# CH585SFR register map
Vendor: WCH Ltd.; Series: CH58x; File version: 1.1
CPU: RISC-V r0p0, little endian, no MPU, no FPU, 2 interrupt priority bits
Registers are 8-bit, read-write, reset 0x0 unless marked. A register's access mark holds for its fields unless they carry their own. Offsets are from the block's base; [hi:lo] are bit positions.

## TMR3 — Timer3 register
Base 0x40002C00
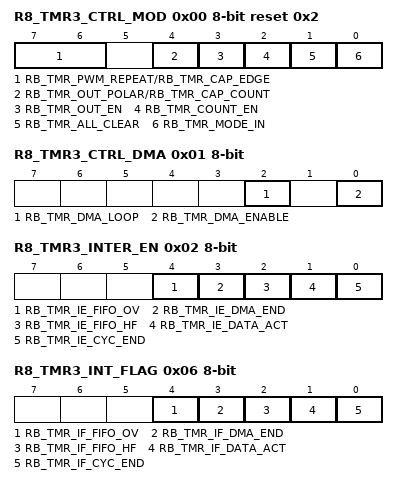
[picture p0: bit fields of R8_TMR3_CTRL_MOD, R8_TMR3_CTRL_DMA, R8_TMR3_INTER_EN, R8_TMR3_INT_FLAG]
0x00 R8_TMR3_CTRL_MOD reset 0x2 — RW, TMR3 mode control
  [7:6] RB_TMR_PWM_REPEAT/RB_TMR_CAP_EDGE — RW, timer PWM repeat mode: 00=1, 01=4, 10=8, 11-16;RW, timer capture edge mode: 00=disable, 01=edge change, 10=fall to fall, 11-rise to rise
  [4] RB_TMR_OUT_POLAR/RB_TMR_CAP_COUNT — RW, timer PWM output polarity: 0=default low and high action, 1=default high and low action;RW, count sub-mode if RB_TMR_MODE_IN=1: 0=capture, 1=count
  [3] RB_TMR_OUT_EN — RW, timer output enable
  [2] RB_TMR_COUNT_EN — RW, timer count enable
  [1] RB_TMR_ALL_CLEAR — RW, force clear timer FIFO and count
  [0] RB_TMR_MODE_IN — RW, timer in mode: 0=timer/PWM, 1=capture/count
0x01 R8_TMR3_CTRL_DMA — RW, TMR3 DMA control
  [2] RB_TMR_DMA_LOOP — RW, timer3 DMA address loop enable
  [0] RB_TMR_DMA_ENABLE — RW, timer3 DMA enable
0x02 R8_TMR3_INTER_EN — RW, TMR3 interrupt enable
  [4] RB_TMR_IE_FIFO_OV — RW, enable interrupt for timer FIFO overflow
  [3] RB_TMR_IE_DMA_END — RW, enable interrupt for timer1/2 DMA completion
  [2] RB_TMR_IE_FIFO_HF — RW, enable interrupt for timer FIFO half (capture fifo more than 4 or PWM fifo less than 3)
  [1] RB_TMR_IE_DATA_ACT — RW, enable interrupt for timer capture input action or PWM trigger
  [0] RB_TMR_IE_CYC_END — RW, enable interrupt for timer capture count timeout or PWM cycle end
0x06 R8_TMR3_INT_FLAG — RW1, TMR3 interrupt flag
  [4] RB_TMR_IF_FIFO_OV — RW1, interrupt flag for timer FIFO overflow
  [3] RB_TMR_IF_DMA_END — RW1, interrupt flag for timer1/2 DMA completion
  [2] RB_TMR_IF_FIFO_HF — RW1, interrupt flag for timer FIFO half (capture fifo more than 4 or PWM fifo less than 3)
  [1] RB_TMR_IF_DATA_ACT — RW1, interrupt flag for timer capture input action or PWM trigger
  [0] RB_TMR_IF_CYC_END — RW1, interrupt flag for timer capture count timeout or PWM cycle end
0x07 R8_TMR3_FIFO_COUNT ro reset not defined — RO, TMR3 FIFO count status
  [3:0] R8_TMR3_FIFO_COUNT
0x08 R32_TMR3_COUNT 32-bit ro reset not defined — RO, TMR3 current count
  [25:0] R32_TMR3_COUNT
0x0C R32_TMR3_CNT_END 32-bit reset not defined — RW, TMR3 end count value, only low 26 bit
0x10 R32_TMR3_FIFO 32-bit reset not defined — RO/WO, TMR3 FIFO register, only low 26 bit
0x14 R16_TMR2_DMA_NOW 16-bit ro reset not defined — RO, TMR2 DMA current address
  [16:2] R16_TMR2_DMA_NOW — RO, DMA data buffer current address
0x18 R16_TMR3_DMA_BEG 16-bit reset not defined — RW, TMR3 DMA begin address
  [16:2] R16_TMR3_DMA_BEG — RW, TMR3 DMA data buffer start address
0x1C R16_TMR3_DMA_END 16-bit reset not defined — RW, TMR3 DMA end address
  [16:2] R16_TMR3_DMA_END — RW, TMR2 DMA end address

## SPI0
Base 0x40004000
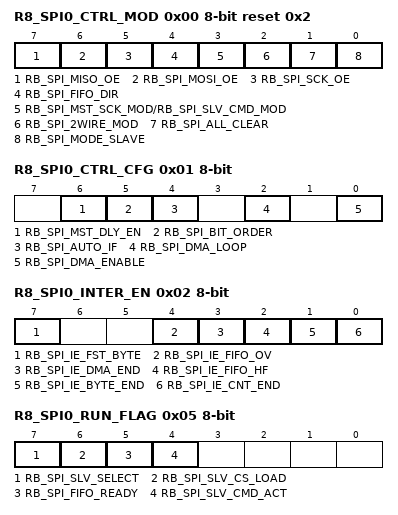
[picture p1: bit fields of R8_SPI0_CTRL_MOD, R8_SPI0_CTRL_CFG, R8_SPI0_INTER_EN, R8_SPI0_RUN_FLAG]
0x00 R8_SPI0_CTRL_MOD reset 0x2 — RW, SPI0 mode control
  [7] RB_SPI_MISO_OE — RW, SPI MISO output enable
  [6] RB_SPI_MOSI_OE — RW, SPI MOSI output enable
  [5] RB_SPI_SCK_OE — RW, SPI SCK output enable
  [4] RB_SPI_FIFO_DIR — RW, SPI FIFO direction: 0=out(write @master mode), 1=in(read @master mode)
  [3] RB_SPI_MST_SCK_MOD/RB_SPI_SLV_CMD_MOD — RW, SPI master clock mode: 0=mode 0, 1=mode 3;RW, SPI0 slave command mode: 0=byte stream, 1=first byte command
  [2] RB_SPI_2WIRE_MOD — RW, SPI0 enable 2 wire mode for slave: 0=3wire(SCK0,MOSI,MISO), 1=2wire(SCK0,MISO=MXSX)
  [1] RB_SPI_ALL_CLEAR — RW, force clear SPI FIFO and count
  [0] RB_SPI_MODE_SLAVE — RW, SPI0 slave mode: 0=master or host, 1=slave or device
0x01 R8_SPI0_CTRL_CFG — RW, SPI0 configuration control
  [6] RB_SPI_MST_DLY_EN — RW, SPI master input delay enable
  [5] RB_SPI_BIT_ORDER — RW, SPI bit data order: 0=MSB first, 1=LSB first
  [4] RB_SPI_AUTO_IF — RW, enable buffer/FIFO accessing to auto clear RB_SPI_IF_BYTE_END interrupt flag
  [2] RB_SPI_DMA_LOOP — RW, SPI0 DMA address loop enable
  [0] RB_SPI_DMA_ENABLE — RW, SPI0 DMA enable
0x02 R8_SPI0_INTER_EN — RW, SPI0 interrupt enable
  [7] RB_SPI_IE_FST_BYTE — RW, enable interrupt for SPI0 slave mode first byte received
  [4] RB_SPI_IE_FIFO_OV — RW, enable interrupt for SPI0 FIFO overflow
  [3] RB_SPI_IE_DMA_END — RW, enable interrupt for SPI0 DMA completion
  [2] RB_SPI_IE_FIFO_HF — RW, enable interrupt for SPI FIFO half
  [1] RB_SPI_IE_BYTE_END — RW, enable interrupt for SPI byte exchanged
  [0] RB_SPI_IE_CNT_END — RW, enable interrupt for SPI total byte count end
0x03 R8_SPI0_CLOCK_DIV/R8_SPI0_SLAVE_PRE reset 0x10 — RW, SPI0 master clock divisor;RW, SPI0 slave preset value
0x04 R8_SPI0_BUFFER reset not defined — RW, SPI0 data buffer
0x05 R8_SPI0_RUN_FLAG ro — RO, SPI0 work flag
  [7] RB_SPI_SLV_SELECT — RO, SPI0 slave selection status
  [6] RB_SPI_SLV_CS_LOAD — RO, SPI0 slave chip-select loading status
  [5] RB_SPI_FIFO_READY — RO, SPI FIFO ready status
  [4] RB_SPI_SLV_CMD_ACT — RO, SPI0 slave first byte or command flag
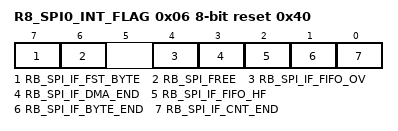
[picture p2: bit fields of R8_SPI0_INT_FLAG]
0x06 R8_SPI0_INT_FLAG reset 0x40 — RW1, SPI0 interrupt flag
  [7] RB_SPI_IF_FST_BYTE — RW1, interrupt flag for SPI0 slave mode first byte received
  [6] RB_SPI_FREE — RO, current SPI free status
  [4] RB_SPI_IF_FIFO_OV — RW1, interrupt flag for SPI0 FIFO overflow
  [3] RB_SPI_IF_DMA_END — RW1, interrupt flag for SPI0 DMA completion
  [2] RB_SPI_IF_FIFO_HF — RW1, interrupt flag for SPI FIFO half
  [1] RB_SPI_IF_BYTE_END — RW1, interrupt flag for SPI byte exchanged
  [0] RB_SPI_IF_CNT_END — RW1, interrupt flag for SPI total byte count end
0x07 R8_SPI0_FIFO_COUNT — RW, SPI0 FIFO count status
  [3:0] R8_SPI0_FIFO_COUNT
0x0C R16_SPI0_TOTAL_CNT 16-bit — RW, SPI0 total byte count, only low 12 bit
  [11:0] R16_SPI0_TOTAL_CNT
0x10 R8_SPI0_FIFO reset not defined — RO/WO, SPI0 FIFO register
0x13 R8_SPI0_FIFO_COUNT1 ro — RO, SPI0 FIFO count status
0x14 R32_SPI0_DMA_NOW 32-bit reset not defined — RW, SPI0 DMA current address
  [16:0] RB_SPI0_DMA_NOW
0x18 R32_SPI0_DMA_BEG 32-bit reset not defined — RW, SPI0 DMA begin address
  [16:0] R32_SPI0_DMA_BEG
0x1C R32_SPI0_DMA_END 32-bit reset not defined — RW, SPI0 DMA end address
  [16:0] R32_SPI0_DMA_END
